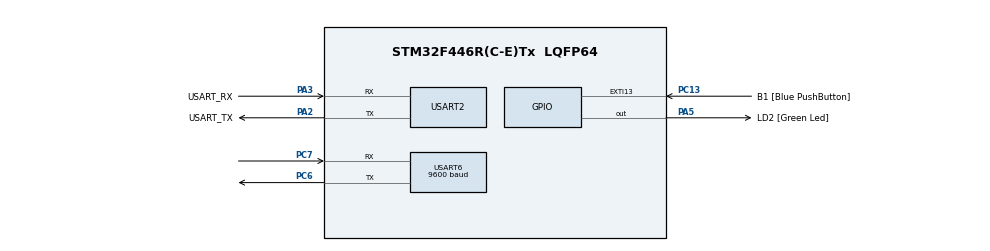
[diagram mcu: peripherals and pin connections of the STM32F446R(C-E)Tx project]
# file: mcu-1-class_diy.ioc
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Mcu.Family=STM32F4
Mcu.Name=STM32F446R(C-E)Tx
Mcu.Package=LQFP64
NVIC.PriorityGroup=NVIC_PRIORITYGROUP_0
PA13.GPIO_Label=TMS
PA13.Mode=Serial_Wire
PA13.Signal=SYS_JTMS-SWDIO
PA14.GPIO_Label=TCK
PA14.Mode=Serial_Wire
PA14.Signal=SYS_JTCK-SWCLK
PA2.GPIO_Label=USART_TX
PA2.Mode=Asynchronous
PA2.Signal=USART2_TX
PA3.GPIO_Label=USART_RX
PA3.Mode=Asynchronous
PA3.Signal=USART2_RX
PA5.GPIO_Label=LD2 [Green Led]
PA5.Signal=GPIO_Output
PB3.GPIO_Label=SWO
PB3.Signal=SYS_JTDO-SWO
PC13.GPIO_Label=B1 [Blue PushButton]
PC13.GPIO_ModeDefaultEXTI=GPIO_MODE_IT_FALLING
PC13.Signal=GPXTI13
PC14-OSC32_IN.Mode=LSE-External-Oscillator
PC14-OSC32_IN.Signal=RCC_OSC32_IN
PC15-OSC32_OUT.Mode=LSE-External-Oscillator
PC15-OSC32_OUT.Signal=RCC_OSC32_OUT
PC6.Mode=Asynchronous
PC6.Signal=USART6_TX
PC7.Mode=Asynchronous
PC7.Signal=USART6_RX
PH0-OSC_IN.Mode=HSE-External-Oscillator
PH0-OSC_IN.Signal=RCC_OSC_IN
PH1-OSC_OUT.Mode=HSE-External-Oscillator
PH1-OSC_OUT.Signal=RCC_OSC_OUT
ProjectManager.HeapSize=0x200
ProjectManager.StackSize=0x400
ProjectManager.TargetToolchain=STM32CubeIDE
RCC.48MHZClocksFreq_Value=84000000
RCC.AHBFreq_Value=180000000
RCC.APB1CLKDivider=RCC_HCLK_DIV4
RCC.APB1Freq_Value=45000000
RCC.APB1TimFreq_Value=90000000
RCC.APB2CLKDivider=RCC_HCLK_DIV2
RCC.APB2Freq_Value=90000000
RCC.APB2TimFreq_Value=180000000
RCC.CortexFreq_Value=180000000
RCC.FLatency-AdvancedSettings=FLASH_LATENCY_5
RCC.HCLKFreq_Value=180000000
RCC.HSE_VALUE=8000000
RCC.HSI_VALUE=16000000
RCC.PLLM=4
RCC.PLLN=180
RCC.PLLSourceVirtual=RCC_PLLSOURCE_HSE
RCC.SYSCLKFreq_VALUE=180000000
RCC.SYSCLKSource=RCC_SYSCLKSOURCE_PLLCLK
RCC.USBFreq_Value=180000000
RCC.VCOOutputFreq_Value=360000000
USART2.VirtualMode=VM_ASYNC
USART6.BaudRate=9600
USART6.VirtualMode=VM_ASYNC
board=NUCLEO-F446RE

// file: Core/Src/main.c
/* USER CODE BEGIN Header */
/**
  ******************************************************************************
  * @file           : main.c
  * @brief          : Main program body
  ******************************************************************************
  * @attention
  *
  * Copyright (c) 2023 STMicroelectronics.
  * All rights reserved.
  *
  * This software is licensed under terms that can be found in the LICENSE file
  * in the root directory of this software component.
  * If no LICENSE file comes with this software, it is provided AS-IS.
  *
  ******************************************************************************
  */
/* USER CODE END Header */
#include "main.h"

UART_HandleTypeDef huart2;
UART_HandleTypeDef huart6;

void SystemClock_Config(void);
static void MX_GPIO_Init(void);
static void MX_USART2_UART_Init(void);
static void MX_USART6_UART_Init(void);
/* USER CODE BEGIN PFP */
#define PUTCHAR_PROTOTYPE int __io_putchar(int ch)
/* USER CODE END PFP */

int main(void)
{

  /* MCU Configuration--------------------------------------------------------*/

  /* Reset of all peripherals, Initializes the Flash interface and the Systick. */
  HAL_Init();

  /* Configure the system clock */
  SystemClock_Config();

  /* Initialize all configured peripherals */
  MX_GPIO_Init();
  MX_USART2_UART_Init();
  MX_USART6_UART_Init();

  /* Infinite loop */
  while (1)
  {

    /* USER CODE BEGIN 3 */
	  printf("Hello World \n");
	  HAL_Delay(1000);
  }
  /* USER CODE END 3 */
}

void SystemClock_Config(void)
{
  LL_FLASH_SetLatency(LL_FLASH_LATENCY_5);
  while(LL_FLASH_GetLatency()!= LL_FLASH_LATENCY_5)
  {
  }
  LL_PWR_SetRegulVoltageScaling(LL_PWR_REGU_VOLTAGE_SCALE1);
  LL_PWR_EnableOverDriveMode();
  LL_RCC_HSE_Enable();

   /* Wait till HSE is ready */
  while(LL_RCC_HSE_IsReady() != 1)
  {

  }
  LL_RCC_PLL_ConfigDomain_SYS(LL_RCC_PLLSOURCE_HSE, LL_RCC_PLLM_DIV_4, 180, LL_RCC_PLLP_DIV_2);
  LL_RCC_PLL_Enable();

   /* Wait till PLL is ready */
  while(LL_RCC_PLL_IsReady() != 1)
  {

  }
  LL_RCC_SetAHBPrescaler(LL_RCC_SYSCLK_DIV_1);
  LL_RCC_SetAPB1Prescaler(LL_RCC_APB1_DIV_4);
  LL_RCC_SetAPB2Prescaler(LL_RCC_APB2_DIV_2);
  LL_RCC_SetSysClkSource(LL_RCC_SYS_CLKSOURCE_PLL);

   /* Wait till System clock is ready */
  while(LL_RCC_GetSysClkSource() != LL_RCC_SYS_CLKSOURCE_STATUS_PLL)
  {

  }
  LL_SetSystemCoreClock(180000000);

   /* Update the time base */
  if (HAL_InitTick (TICK_INT_PRIORITY) != HAL_OK)
  {
    Error_Handler();
  }
  LL_RCC_SetTIMPrescaler(LL_RCC_TIM_PRESCALER_TWICE);
}

static void MX_USART2_UART_Init(void)
{

  huart2.Instance = USART2;
  huart2.Init.BaudRate = 115200;
  huart2.Init.WordLength = UART_WORDLENGTH_8B;
  huart2.Init.StopBits = UART_STOPBITS_1;
  huart2.Init.Parity = UART_PARITY_NONE;
  huart2.Init.Mode = UART_MODE_TX_RX;
  huart2.Init.HwFlowCtl = UART_HWCONTROL_NONE;
  huart2.Init.OverSampling = UART_OVERSAMPLING_16;
  if (HAL_UART_Init(&huart2) != HAL_OK)
  {
    Error_Handler();
  }

}

static void MX_USART6_UART_Init(void)
{

  huart6.Instance = USART6;
  huart6.Init.BaudRate = 9600;
  huart6.Init.WordLength = UART_WORDLENGTH_8B;
  huart6.Init.StopBits = UART_STOPBITS_1;
  huart6.Init.Parity = UART_PARITY_NONE;
  huart6.Init.Mode = UART_MODE_TX_RX;
  huart6.Init.HwFlowCtl = UART_HWCONTROL_NONE;
  huart6.Init.OverSampling = UART_OVERSAMPLING_16;
  if (HAL_UART_Init(&huart6) != HAL_OK)
  {
    Error_Handler();
  }

}

static void MX_GPIO_Init(void)
{
  LL_EXTI_InitTypeDef EXTI_InitStruct = {0};
  LL_GPIO_InitTypeDef GPIO_InitStruct = {0};

  /* GPIO Ports Clock Enable */
  LL_AHB1_GRP1_EnableClock(LL_AHB1_GRP1_PERIPH_GPIOC);
  LL_AHB1_GRP1_EnableClock(LL_AHB1_GRP1_PERIPH_GPIOH);
  LL_AHB1_GRP1_EnableClock(LL_AHB1_GRP1_PERIPH_GPIOA);
  LL_AHB1_GRP1_EnableClock(LL_AHB1_GRP1_PERIPH_GPIOB);

  /**/
  LL_GPIO_ResetOutputPin(LD2_GPIO_Port, LD2_Pin);

  /**/
  LL_SYSCFG_SetEXTISource(LL_SYSCFG_EXTI_PORTC, LL_SYSCFG_EXTI_LINE13);

  /**/
  EXTI_InitStruct.Line_0_31 = LL_EXTI_LINE_13;
  EXTI_InitStruct.LineCommand = ENABLE;
  EXTI_InitStruct.Mode = LL_EXTI_MODE_IT;
  EXTI_InitStruct.Trigger = LL_EXTI_TRIGGER_FALLING;
  LL_EXTI_Init(&EXTI_InitStruct);

  /**/
  LL_GPIO_SetPinPull(B1_GPIO_Port, B1_Pin, LL_GPIO_PULL_NO);

  /**/
  LL_GPIO_SetPinMode(B1_GPIO_Port, B1_Pin, LL_GPIO_MODE_INPUT);

  /**/
  GPIO_InitStruct.Pin = LD2_Pin;
  GPIO_InitStruct.Mode = LL_GPIO_MODE_OUTPUT;
  GPIO_InitStruct.Speed = LL_GPIO_SPEED_FREQ_LOW;
  GPIO_InitStruct.OutputType = LL_GPIO_OUTPUT_PUSHPULL;
  GPIO_InitStruct.Pull = LL_GPIO_PULL_NO;
  LL_GPIO_Init(LD2_GPIO_Port, &GPIO_InitStruct);

}

/* USER CODE BEGIN 4 */
/**
  * @brief  Retargets the C library printf function to the USART.
  * @param  None
  * @retval None
  */
PUTCHAR_PROTOTYPE
{
  /* Place your implementation of fputc here */
  /* e.g. write a character to the USART1 and Loop until the end of transmission */
  HAL_UART_Transmit(&huart2, (uint8_t *)&ch, 1, 0xFFFF);

  return ch;
}
/* USER CODE END 4 */

void Error_Handler(void)
{
  __disable_irq();
  while (1)
  {
  }
}
